AUTOSAR XML (schema 4-2-2)
package /ARRoot
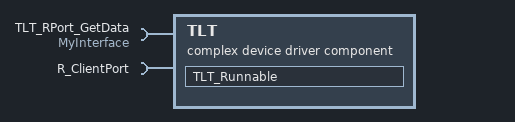
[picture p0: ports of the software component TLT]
  complex device driver sw component type TLT
    require port TLT_RPort_GetData: nonqueued-receiver-com-spec=data-element=MyInterface, required-interface=MyInterface
    require port R_ClientPort: required-com-specs=[Operation1, Operation2]
    swc-internal-behavior timing-event{start-on-event=TLT_Runnable, period=0.01}:
      runnable TLT_Runnable: data-receive-point-by-values=variable-access=accessed-variable=TLT_RPort_GetData, server-call-points=[R_ClientPort.Operation1, R_ClientPort.Operation2], symbol=TLT_vRunnable
  swc-implementation behavior=/ARRoot/SPD/:
    code-descriptors:
      code Code
    resource consumption ResourceConsumption
